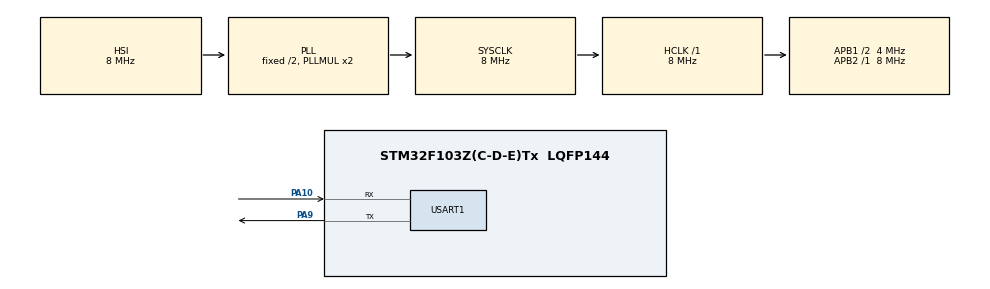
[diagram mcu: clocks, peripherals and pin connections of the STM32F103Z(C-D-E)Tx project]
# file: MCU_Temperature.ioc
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ADC1.Channel-0\#ChannelRegularConversion=ADC_CHANNEL_TEMPSENSOR
ADC1.ContinuousConvMode=DISABLE
ADC1.DataAlign=ADC_DATAALIGN_RIGHT
ADC1.DiscontinuousConvMode=DISABLE
ADC1.EnableAnalogWatchDog=false
ADC1.EnableRegularConversion=ENABLE
ADC1.ExternalTrigConv=ADC_EXTERNALTRIGCONV_T1_CC1
ADC1.InjNumberOfConversion=0
ADC1.NbrOfConversion=1
ADC1.NbrOfConversionFlag=1
ADC1.Rank-0\#ChannelRegularConversion=1
ADC1.SamplingTime-0\#ChannelRegularConversion=ADC_SAMPLETIME_1CYCLE_5
ADC1.ScanConvMode=ADC_SCAN_DISABLE
ADC1.master=1
Mcu.Family=STM32F1
Mcu.Name=STM32F103Z(C-D-E)Tx
Mcu.Package=LQFP144
NVIC.PriorityGroup=NVIC_PRIORITYGROUP_4
PA10.Mode=Asynchronous
PA10.Signal=USART1_RX
PA9.Mode=Asynchronous
PA9.Signal=USART1_TX
ProjectManager.HeapSize=0x200
ProjectManager.StackSize=0x400
ProjectManager.TargetToolchain=MDK-ARM V5
RCC.ADCPresc=RCC_ADCPCLK2_DIV4
RCC.AHBFreq_Value=8000000
RCC.APB1CLKDivider=RCC_HCLK_DIV2
RCC.APB1Freq_Value=4000000
RCC.APB1TimFreq_Value=8000000
RCC.APB2Freq_Value=8000000
RCC.APB2TimFreq_Value=8000000
RCC.HCLKFreq_Value=8000000
RCC.SYSCLKFreq_VALUE=8000000
RCC.SYSCLKSource=RCC_SYSCLKSOURCE_PLLCLK
RCC.USBFreq_Value=8000000
VP_ADC1_TempSens_Input.Mode=IN-TempSens
VP_SYS_VS_ND.Mode=No_Debug
board=MCU_Temperature

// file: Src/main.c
/**
  ******************************************************************************
  * File Name          : main.c
  * Description        : Main program body
  ******************************************************************************
  *
  * COPYRIGHT(c) 2017 STMicroelectronics
  *
  * Redistribution and use in source and binary forms, with or without modification,
  * are permitted provided that the following conditions are met:
  *   1. Redistributions of source code must retain the above copyright notice,
  *      this list of conditions and the following disclaimer.
  *   2. Redistributions in binary form must reproduce the above copyright notice,
  *      this list of conditions and the following disclaimer in the documentation
  *      and/or other materials provided with the distribution.
  *   3. Neither the name of STMicroelectronics nor the names of its contributors
  *      may be used to endorse or promote products derived from this software
  *      without specific prior written permission.
  *
  * THIS SOFTWARE IS PROVIDED BY THE COPYRIGHT HOLDERS AND CONTRIBUTORS "AS IS"
  * AND ANY EXPRESS OR IMPLIED WARRANTIES, INCLUDING, BUT NOT LIMITED TO, THE
  * IMPLIED WARRANTIES OF MERCHANTABILITY AND FITNESS FOR A PARTICULAR PURPOSE ARE
  * DISCLAIMED. IN NO EVENT SHALL THE COPYRIGHT HOLDER OR CONTRIBUTORS BE LIABLE
  * FOR ANY DIRECT, INDIRECT, INCIDENTAL, SPECIAL, EXEMPLARY, OR CONSEQUENTIAL
  * DAMAGES (INCLUDING, BUT NOT LIMITED TO, PROCUREMENT OF SUBSTITUTE GOODS OR
  * SERVICES; LOSS OF USE, DATA, OR PROFITS; OR BUSINESS INTERRUPTION) HOWEVER
  * CAUSED AND ON ANY THEORY OF LIABILITY, WHETHER IN CONTRACT, STRICT LIABILITY,
  * OR TORT (INCLUDING NEGLIGENCE OR OTHERWISE) ARISING IN ANY WAY OUT OF THE USE
  * OF THIS SOFTWARE, EVEN IF ADVISED OF THE POSSIBILITY OF SUCH DAMAGE.
  *
  ******************************************************************************
  */
#include "main.h"
#include "stm32f1xx_hal.h"
#include "adc.h"
#include "usart.h"
#include "gpio.h"

/* USER CODE BEGIN PV */
/* Private variables ---------------------------------------------------------*/

/* USER CODE END PV */

void SystemClock_Config(void);
void Error_Handler(void);

/* USER CODE BEGIN PFP */
/* Private function prototypes -----------------------------------------------*/

/* USER CODE END PFP */

int main(void)
{

  /* USER CODE BEGIN 1 */
  uint32_t AD_Value = 0;
  /* USER CODE END 1 */

  /* MCU Configuration----------------------------------------------------------*/

  /* Reset of all peripherals, Initializes the Flash interface and the Systick. */
  HAL_Init();

  /* Configure the system clock */
  SystemClock_Config();

  /* Initialize all configured peripherals */
  MX_GPIO_Init();
  MX_USART1_UART_Init();
  MX_ADC1_Init();

  /* USER CODE BEGIN 2 */
  /* Run the ADC calibration */
  HAL_ADCEx_Calibration_Start(&hadc1);
  /* USER CODE END 2 */

  /* Infinite loop */
  while (1)
  {

  /* USER CODE BEGIN 3 */

    /*##-1- Start the conversion process #######################################*/
    HAL_ADC_Start(&hadc1);

    /*##-2- Wait for the end of conversion #####################################*/
    /*  Before starting a new conversion, you need to check the current state of
         the peripheral; if it? busy you need to wait for the end of current
         conversion before starting a new one.
         For simplicity reasons, this example is just waiting till the end of the
         conversion, but application may perform other tasks while conversion
         operation is ongoing. */
    HAL_ADC_PollForConversion(&hadc1, 1);

    /*##-3- Get the converted value of regular channel  ######################*/
    AD_Value = HAL_ADC_GetValue(&hadc1);

    printf("MCU Temperature : %.1f C\r\n", ((1.43 - 3.3 / 4095 * AD_Value) / 0.0043 + 25));    HAL_Delay(1000);
  }
  /* USER CODE END 3 */

}

/** System Clock Configuration
*/
void SystemClock_Config(void)
{

  RCC_OscInitTypeDef RCC_OscInitStruct;
  RCC_ClkInitTypeDef RCC_ClkInitStruct;
  RCC_PeriphCLKInitTypeDef PeriphClkInit;

    /**Initializes the CPU, AHB and APB busses clocks
    */
  RCC_OscInitStruct.OscillatorType = RCC_OSCILLATORTYPE_HSI;
  RCC_OscInitStruct.HSIState = RCC_HSI_ON;
  RCC_OscInitStruct.HSICalibrationValue = 16;
  RCC_OscInitStruct.PLL.PLLState = RCC_PLL_ON;
  RCC_OscInitStruct.PLL.PLLSource = RCC_PLLSOURCE_HSI_DIV2;
  RCC_OscInitStruct.PLL.PLLMUL = RCC_PLL_MUL2;
  if (HAL_RCC_OscConfig(&RCC_OscInitStruct) != HAL_OK)
  {
    Error_Handler();
  }

    /**Initializes the CPU, AHB and APB busses clocks
    */
  RCC_ClkInitStruct.ClockType = RCC_CLOCKTYPE_HCLK|RCC_CLOCKTYPE_SYSCLK
                              |RCC_CLOCKTYPE_PCLK1|RCC_CLOCKTYPE_PCLK2;
  RCC_ClkInitStruct.SYSCLKSource = RCC_SYSCLKSOURCE_PLLCLK;
  RCC_ClkInitStruct.AHBCLKDivider = RCC_SYSCLK_DIV1;
  RCC_ClkInitStruct.APB1CLKDivider = RCC_HCLK_DIV2;
  RCC_ClkInitStruct.APB2CLKDivider = RCC_HCLK_DIV1;

  if (HAL_RCC_ClockConfig(&RCC_ClkInitStruct, FLASH_LATENCY_0) != HAL_OK)
  {
    Error_Handler();
  }

  PeriphClkInit.PeriphClockSelection = RCC_PERIPHCLK_ADC;
  PeriphClkInit.AdcClockSelection = RCC_ADCPCLK2_DIV4;
  if (HAL_RCCEx_PeriphCLKConfig(&PeriphClkInit) != HAL_OK)
  {
    Error_Handler();
  }

    /**Configure the Systick interrupt time
    */
  HAL_SYSTICK_Config(HAL_RCC_GetHCLKFreq()/1000);

    /**Configure the Systick
    */
  HAL_SYSTICK_CLKSourceConfig(SYSTICK_CLKSOURCE_HCLK);

  /* SysTick_IRQn interrupt configuration */
  HAL_NVIC_SetPriority(SysTick_IRQn, 0, 0);
}

void Error_Handler(void)
{
  while(1)
  {
  }
}

/************************ (C) COPYRIGHT STMicroelectronics *****END OF FILE****/
